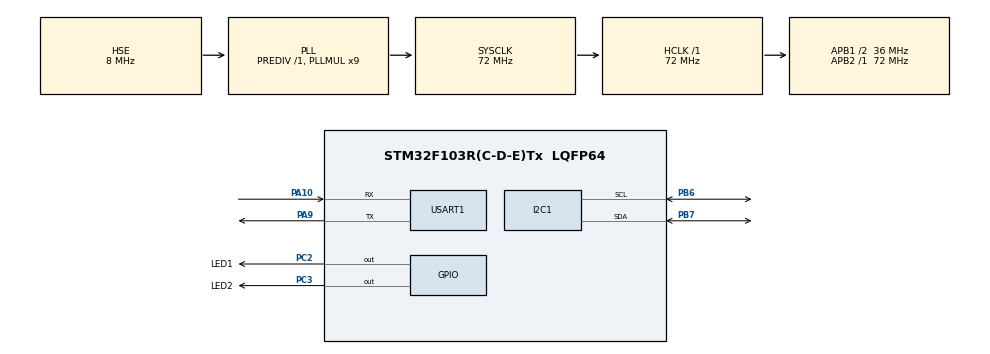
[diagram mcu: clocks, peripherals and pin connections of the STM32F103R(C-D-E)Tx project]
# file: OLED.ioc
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Mcu.Family=STM32F1
Mcu.Name=STM32F103R(C-D-E)Tx
Mcu.Package=LQFP64
NVIC.PriorityGroup=NVIC_PRIORITYGROUP_4
NVIC.USART1_IRQn=true\:0\:0\:false\:false\:true\:true\:true
PA10.Mode=Asynchronous
PA10.Signal=USART1_RX
PA13.Mode=Serial_Wire
PA13.Signal=SYS_JTMS-SWDIO
PA14.Mode=Serial_Wire
PA14.Signal=SYS_JTCK-SWCLK
PA9.Mode=Asynchronous
PA9.Signal=USART1_TX
PB6.Mode=I2C
PB6.Signal=I2C1_SCL
PB7.Mode=I2C
PB7.Signal=I2C1_SDA
PC2.GPIO_Label=LED1
PC2.Signal=GPIO_Output
PC3.GPIO_Label=LED2
PC3.Signal=GPIO_Output
PD0-OSC_IN.Mode=HSE-External-Oscillator
PD0-OSC_IN.Signal=RCC_OSC_IN
PD1-OSC_OUT.Mode=HSE-External-Oscillator
PD1-OSC_OUT.Signal=RCC_OSC_OUT
ProjectManager.HeapSize=0x200
ProjectManager.StackSize=0x400
ProjectManager.TargetToolchain=SW4STM32
RCC.AHBFreq_Value=72000000
RCC.APB1CLKDivider=RCC_HCLK_DIV2
RCC.APB1Freq_Value=36000000
RCC.APB1TimFreq_Value=72000000
RCC.APB2Freq_Value=72000000
RCC.APB2TimFreq_Value=72000000
RCC.HCLKFreq_Value=72000000
RCC.PLLMUL=RCC_PLL_MUL9
RCC.PLLSourceVirtual=RCC_PLLSOURCE_HSE
RCC.SYSCLKFreq_VALUE=72000000
RCC.SYSCLKSource=RCC_SYSCLKSOURCE_PLLCLK
RCC.USBFreq_Value=72000000
USART1.VirtualMode=VM_ASYNC
board=custom

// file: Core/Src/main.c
/* USER CODE BEGIN Header */
/**
  ******************************************************************************
  * @file           : main.c
  * @brief          : Main program body
  ******************************************************************************
  * @attention
  *
  * <h2><center>&copy; Copyright (c) 2022 STMicroelectronics.
  * All rights reserved.</center></h2>
  *
  * This software component is licensed by ST under BSD 3-Clause license,
  * the "License"; You may not use this file except in compliance with the
  * License. You may obtain a copy of the License at:
  *                        opensource.org/licenses/BSD-3-Clause
  *
  ******************************************************************************
  */
/* USER CODE END Header */
#include "main.h"

/* USER CODE BEGIN Includes */
#include "retarget.h"
#include "oled.h"
/* USER CODE END Includes */

I2C_HandleTypeDef hi2c1;

UART_HandleTypeDef huart1;

void SystemClock_Config(void);
static void MX_GPIO_Init(void);
static void MX_I2C1_Init(void);
static void MX_USART1_UART_Init(void);

int main(void)
{

  /* MCU Configuration--------------------------------------------------------*/

  /* Reset of all peripherals, Initializes the Flash interface and the Systick. */
  HAL_Init();

  /* Configure the system clock */
  SystemClock_Config();

  /* Initialize all configured peripherals */
  MX_GPIO_Init();
  MX_I2C1_Init();
  MX_USART1_UART_Init();
  /* USER CODE BEGIN 2 */
    OLED_Init();                           //OLED初始
    OLED_Clear();                          //清屏
  printf("OLED Project");
//  OLED_ShowString(0,0,"UNICORN_LI",16, 0);    //反相显示8X16字符�?
//  OLED_ShowString(0,2,"unicorn_li_123",12,0);//正相显示6X8字符�?
//  OLED_ShowCHinese(0,4,0,1); //反相显示汉字“独�?
//  OLED_ShowCHinese(16,4,1,1);//反相显示汉字“角�?
//  OLED_ShowCHinese(32,4,2,1);//反相显示汉字“兽�?
//  OLED_ShowCHinese(0,6,0,0); //正相显示汉字“独�?
//  OLED_ShowCHinese(16,6,1,0);//正相显示汉字“角�?
//  OLED_ShowCHinese(32,6,2,0);//正相显示汉字“兽�?
//
//  OLED_ShowNum(48,4,6,1,16, 0);//正相显示1�?8X16数字�?6�?
//  OLED_ShowNum(48,7,77,2,12, 1);//反相显示2�?6X8数字�?77�?
//    OLED_ShowNum(48, 4, 6, 1, 16, 0);
//    OLED_DrawBMP(90,4,122, 8,BMP1,0);//正相显示图片BMP1
    OLED_DrawBMP(0,1,64, 8,gImage_dinosaur,0);//正相显示图片
//  OLED_DrawBMP(90,4,122, 8,BMP1,1);//反相显示图片BMP1

  OLED_HorizontalShift(0x26);//全屏水平向右滚动播放
  /* USER CODE END 2 */

  /* Infinite loop */
  while (1)
  {

  }
}

void SystemClock_Config(void)
{
  RCC_OscInitTypeDef RCC_OscInitStruct = {0};
  RCC_ClkInitTypeDef RCC_ClkInitStruct = {0};

  /** Initializes the RCC Oscillators according to the specified parameters
  * in the RCC_OscInitTypeDef structure.
  */
  RCC_OscInitStruct.OscillatorType = RCC_OSCILLATORTYPE_HSE;
  RCC_OscInitStruct.HSEState = RCC_HSE_ON;
  RCC_OscInitStruct.HSEPredivValue = RCC_HSE_PREDIV_DIV1;
  RCC_OscInitStruct.HSIState = RCC_HSI_ON;
  RCC_OscInitStruct.PLL.PLLState = RCC_PLL_ON;
  RCC_OscInitStruct.PLL.PLLSource = RCC_PLLSOURCE_HSE;
  RCC_OscInitStruct.PLL.PLLMUL = RCC_PLL_MUL9;
  if (HAL_RCC_OscConfig(&RCC_OscInitStruct) != HAL_OK)
  {
    Error_Handler();
  }
  /** Initializes the CPU, AHB and APB buses clocks
  */
  RCC_ClkInitStruct.ClockType = RCC_CLOCKTYPE_HCLK|RCC_CLOCKTYPE_SYSCLK
                              |RCC_CLOCKTYPE_PCLK1|RCC_CLOCKTYPE_PCLK2;
  RCC_ClkInitStruct.SYSCLKSource = RCC_SYSCLKSOURCE_PLLCLK;
  RCC_ClkInitStruct.AHBCLKDivider = RCC_SYSCLK_DIV1;
  RCC_ClkInitStruct.APB1CLKDivider = RCC_HCLK_DIV2;
  RCC_ClkInitStruct.APB2CLKDivider = RCC_HCLK_DIV1;

  if (HAL_RCC_ClockConfig(&RCC_ClkInitStruct, FLASH_LATENCY_2) != HAL_OK)
  {
    Error_Handler();
  }
}

static void MX_I2C1_Init(void)
{

  hi2c1.Instance = I2C1;
  hi2c1.Init.ClockSpeed = 100000;
  hi2c1.Init.DutyCycle = I2C_DUTYCYCLE_2;
  hi2c1.Init.OwnAddress1 = 0;
  hi2c1.Init.AddressingMode = I2C_ADDRESSINGMODE_7BIT;
  hi2c1.Init.DualAddressMode = I2C_DUALADDRESS_DISABLE;
  hi2c1.Init.OwnAddress2 = 0;
  hi2c1.Init.GeneralCallMode = I2C_GENERALCALL_DISABLE;
  hi2c1.Init.NoStretchMode = I2C_NOSTRETCH_DISABLE;
  if (HAL_I2C_Init(&hi2c1) != HAL_OK)
  {
    Error_Handler();
  }

}

static void MX_USART1_UART_Init(void)
{

  huart1.Instance = USART1;
  huart1.Init.BaudRate = 115200;
  huart1.Init.WordLength = UART_WORDLENGTH_8B;
  huart1.Init.StopBits = UART_STOPBITS_1;
  huart1.Init.Parity = UART_PARITY_NONE;
  huart1.Init.Mode = UART_MODE_TX_RX;
  huart1.Init.HwFlowCtl = UART_HWCONTROL_NONE;
  huart1.Init.OverSampling = UART_OVERSAMPLING_16;
  if (HAL_UART_Init(&huart1) != HAL_OK)
  {
    Error_Handler();
  }

}

static void MX_GPIO_Init(void)
{
  GPIO_InitTypeDef GPIO_InitStruct = {0};

  /* GPIO Ports Clock Enable */
  __HAL_RCC_GPIOD_CLK_ENABLE();
  __HAL_RCC_GPIOC_CLK_ENABLE();
  __HAL_RCC_GPIOA_CLK_ENABLE();
  __HAL_RCC_GPIOB_CLK_ENABLE();

  /*Configure GPIO pin Output Level */
  HAL_GPIO_WritePin(GPIOC, LED1_Pin|LED2_Pin, GPIO_PIN_RESET);

  /*Configure GPIO pins : LED1_Pin LED2_Pin */
  GPIO_InitStruct.Pin = LED1_Pin|LED2_Pin;
  GPIO_InitStruct.Mode = GPIO_MODE_OUTPUT_PP;
  GPIO_InitStruct.Pull = GPIO_NOPULL;
  GPIO_InitStruct.Speed = GPIO_SPEED_FREQ_LOW;
  HAL_GPIO_Init(GPIOC, &GPIO_InitStruct);

}

void Error_Handler(void)
{
  __disable_irq();
  while (1)
  {
  }
}

/************************ (C) COPYRIGHT STMicroelectronics *****END OF FILE****/
